# ipro7 register map
Vendor: intelpro; Series: BTBLE
CPU: ipro7, little endian
Registers are 32-bit, read-write, reset 0x0 unless marked. A register's access mark holds for its fields unless they carry their own. Offsets are from the block's base; [hi:lo] are bit positions.

## IR
Base 0x30011000
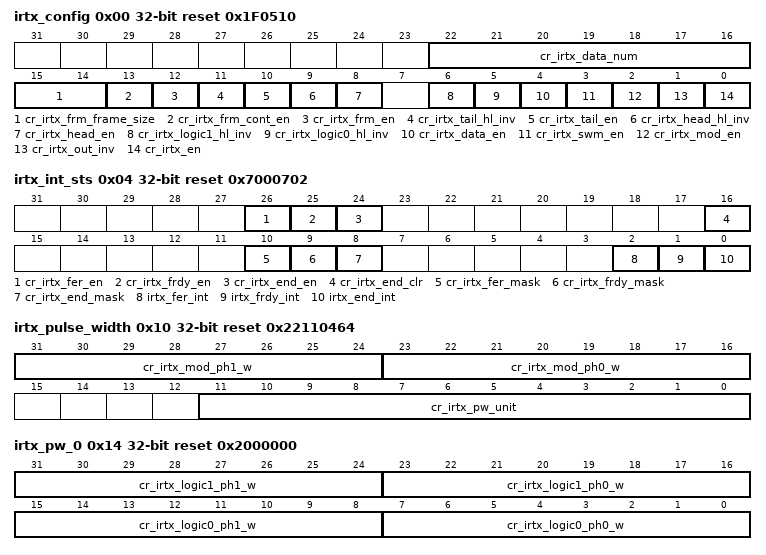
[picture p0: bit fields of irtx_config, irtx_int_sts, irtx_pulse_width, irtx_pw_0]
0x00 irtx_config reset 0x1F0510
  [22:16] cr_irtx_data_num — Bit count of Data phase (unit: bit / PW for normal / SWM) (Don't-care if cr_irtx_frm_en is enabled)
  [15:14] cr_irtx_frm_frame_size — IRTX freerun mode frame size (also the valid width for each FIFO entry) 2'd0: 8-bit 2'd1: 16-bit 2'd2: 24-bit 2'd3: 32-bit
  [13] cr_irtx_frm_cont_en — Enable signal of IRTX freerun continuous mode 0: Disabled, each data frame is separated by an idle time (tail_ph0_w+1 + tail_ph1_w+1)*pw_unit 1: Enabled, data continuously sent without interval (if FIFO data is valid)
  [12] cr_irtx_frm_en — Enable signal of IRTX freerun mode (Don't care if SWM is enabled) Note: HEAD/TAIL is disabled in freerun mode
  [11] cr_irtx_tail_hl_inv — Tail pulse H/L inverse signal (Don't care if SWM or FRM is enabled) 0: Phase 0 is High (Active), phase 1 is Low (Idle) (H -> L) 1: Phase 0 is Low (Idle), phase 1 is High (Active) (L -> H)
  [10] cr_irtx_tail_en — Enable signal of tail pulse (Don't care if SWM or FRM is enabled)
  [9] cr_irtx_head_hl_inv — Tail pulse H/L inverse signal (Don't care if SWM or FRM is enabled) 0: Phase 0 is High (Active), phase 1 is Low (Idle) (H -> L) 1: Phase 0 is Low (Idle), phase 1 is High (Active) (L -> H)
  [8] cr_irtx_head_en — Enable signal of head pulse (Don't care if SWM or FRM is enabled)
  [6] cr_irtx_logic1_hl_inv — Logic 1 H/L inverse signal (Don't care if SWM is enabled) 0: Phase 0 is High (Active), phase 1 is Low (Idle) (H -> L) 1: Phase 0 is Low (Idle), phase 1 is High (Active) (L -> H)
  [5] cr_irtx_logic0_hl_inv — Logic 0 H/L inverse signal (Don't care if SWM is enabled) 0: Phase 0 is High (Active), phase 1 is Low (Idle) (H -> L) 1: Phase 0 is Low (Idle), phase 1 is High (Active) (L -> H)
  [4] cr_irtx_data_en — Enable signal of data phase (Don't care if SWM or FRM is enabled)
  [3] cr_irtx_swm_en — Enable signal of IRTX Software Mode (SWM)
  [2] cr_irtx_mod_en — Enable signal of output modulation
  [1] cr_irtx_out_inv — Output inverse signal 1'b0: Output stays at Low during idle state 1'b1: Output stays at High during idle state
  [0] cr_irtx_en — Enable signal of IRTX function Asserting this bit will trigger the transaction, and should be de-asserted after finish
0x04 irtx_int_sts reset 0x7000702 (reset mask 0xFFFFFFF8)
  [26] cr_irtx_fer_en — Interrupt enable of irtx_fer_int
  [25] cr_irtx_frdy_en — Interrupt enable of irtx_frdy_int
  [24] cr_irtx_end_en — Interrupt enable of irtx_end_int
  [16] cr_irtx_end_clr — Interrupt clear of irtx_end_int
  [10] cr_irtx_fer_mask — Interrupt mask of irtx_fer_int
  [9] cr_irtx_frdy_mask — Interrupt mask of irtx_frdy_int
  [8] cr_irtx_end_mask — Interrupt mask of irtx_end_int
  [2] irtx_fer_int ro — IRTX FIFO error interrupt, auto-cleared when FIFO overflow/underflow error flag is cleared
  [1] irtx_frdy_int ro — IRTX FIFO ready (tx_fifo_cnt > tx_fifo_th) interrupt, auto-cleared when data is pushed
  [0] irtx_end_int ro — IRTX transfer end interrupt
0x10 irtx_pulse_width reset 0x22110464
  [31:24] cr_irtx_mod_ph1_w — Modulation phase 1 width
  [23:16] cr_irtx_mod_ph0_w — Modulation phase 0 width
  [11:0] cr_irtx_pw_unit — Pulse width unit
0x14 irtx_pw_0 reset 0x2000000
  [31:24] cr_irtx_logic1_ph1_w — Pulse width of logic1 phase 1 (Don't care if SWM is enabled)
  [23:16] cr_irtx_logic1_ph0_w — Pulse width of logic1 phase 0 (Don't care if SWM is enabled)
  [15:8] cr_irtx_logic0_ph1_w — Pulse width of logic0 phase 1 (Don't care if SWM is enabled)
  [7:0] cr_irtx_logic0_ph0_w — Pulse width of logic0 phase 0 (Don't care if SWM is enabled)
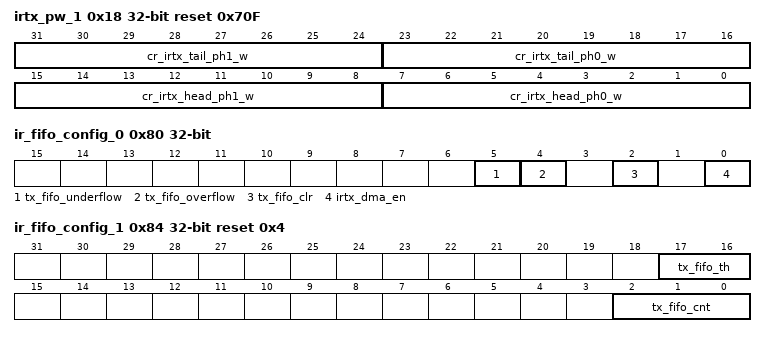
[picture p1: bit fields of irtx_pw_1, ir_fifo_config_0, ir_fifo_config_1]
0x18 irtx_pw_1 reset 0x70F
  [31:24] cr_irtx_tail_ph1_w — Pulse width of tail pulse phase 1 (Don't care if SWM is enabled)
  [23:16] cr_irtx_tail_ph0_w — Pulse width of tail pulse phase 0 (Don't care if SWM is enabled)
  [15:8] cr_irtx_head_ph1_w — Pulse width of head pulse phase 1 (Don't care if SWM is enabled)
  [7:0] cr_irtx_head_ph0_w — Pulse width of head pulse phase 0 (Don't care if SWM is enabled)
0x80 ir_fifo_config_0 (reset mask 0xFFFFFFCF)
  [5] tx_fifo_underflow ro — Underflow flag of TX FIFO, can be cleared by tx_fifo_clr
  [4] tx_fifo_overflow ro — Overflow flag of TX FIFO, can be cleared by tx_fifo_clr
  [2] tx_fifo_clr — Clear signal of TX FIFO
  [0] irtx_dma_en — Enable signal of dma_tx_req/ack interface
0x84 ir_fifo_config_1 reset 0x4 (reset mask 0xFFFFFFF8)
  [17:16] tx_fifo_th — TX FIFO threshold, irtx_frdy_int & dma_tx_req will not be asserted if tx_fifo_cnt is less than this value
  [2:0] tx_fifo_cnt ro — TX FIFO available count
0x88 ir_fifo_wdata
  [31:0] tx_fifo_wdata wo — IRTX FIFO data Normal Mode: Each entry contains a 32-bit data word, LSB is sent first Software Mode: Each entry contains 4 pulse widths, [7:0] is the 1st pulse, [15:8] is the 2nd pulse, etc)
